# IWRL6432 register map
File version: 1.0
IWRL6432 Radar
CPU: CM4 1.0, other endian, MPU, FPU, 3 interrupt priority bits
Registers are 32-bit, read-write, reset 0x0 unless marked. A register's access mark holds for its fields unless they carry their own. Offsets are from the block's base; lines under a group give offsets from that group; [hi:lo] are bit positions; {n}, {i} and the like mark numbered series; 'fields as' and 'values as' point back to an identical list; <NAME> marks a mode.

## Memory map
0x50F7FC00 GPADC_CTRL size 0x5C
0x53000000 APP_LIN size 0x94
0x53F7F000 APP_UART_0 size 0x94 — APP_UART
0x53F7F400 APP_SPI_0 size 0x1A4 — APP_SPI
0x53F7F800 APP_CANCFG size 0x300
0x53F7FC00 APP_CANECC size 0x310
0x54000000 TPTC_A0 size 0x35C — Register test environment
0x54010000 TPTC_A1 size 0x35C — Register test environment
0x54020000 APP_CRC size 0x148
0x55010000 HWA_CFG size 0x3D8
0x55020000 TPTC_B0 size 0x35C — Register test environment
0x55040000 TPTC_B0_1 size 0x35C — Register test environment
0x55080000 TPCC_B size 0x4020 — TPCC
0x56000000 TPCC_A size 0x4020 — TPCC
0x56040000 APP_RCM size 0x1034
0x56060000 APP_CTRL size 0x1034
0x56080000 APP_HWA_ADCBUF_CTRL size 0x1034
0x56F7EC00 APP_ECC_AGG size 0x310
0x56F7F000 APP_RTI size 0xC0
0x56F7F400 APP_WD size 0xC0
0x56F7F800 APP_DCC size 0x3B
0x56F7FC00 APP_ESM size 0xDC
0x57F7F000 APP_UART_1 size 0x94 — APP_UART
0x57F7F400 APP_SPI_1 size 0x1A4 — APP_SPI
0x57F7F800 APP_I2C size 0x64
0x57F7FC00 APP_PWM size 0x74
0x5A000000 TOP_IO_MUX size 0x70
0x5A040000 APP_PRCM size 0x1C30
0x5AF7FC00 TOP_GIO size 0x154
0x5B020000 TOPSS_CTRL size 0x1034
0x5B040000 PLLDIG_CTRL size 0x1034
0x5C020000 PBIST size 0x1D0
0x5CA00000 TOP_DEBUGSS size 0x12000
0x78000000 APP_CFG_QSPI size 0x74

## TOP_IO_MUX
Base 0x5A000000
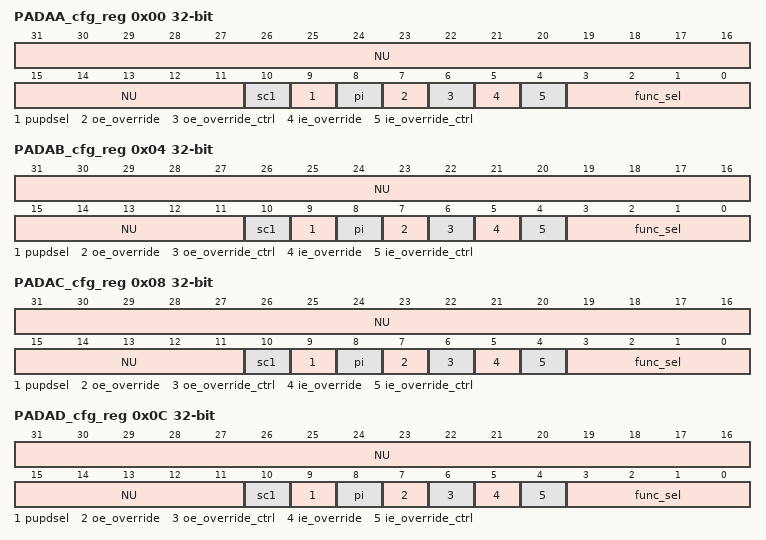
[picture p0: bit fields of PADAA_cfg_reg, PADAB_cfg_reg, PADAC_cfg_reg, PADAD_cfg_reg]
0x00 PADAA_cfg_reg
  [31:11] NU — [31:11] Reserved
  [10] sc1 — [10:10] IO Slew rate control : 0 : higher slew rate. 1: Lower slew rate.
  [9] pupdsel — [9:9] Pullup/PullDown Selection 0 -- Pull Down
  [8] pi — [8:8] Pull Inhibit/Pull Disable 0 -- Enable
  [7] oe_override — [7:7] Active Low Output Override, 0: Output is enabled 1: Output disabled
  [6] oe_override_ctrl — [6:6] Active Low Output Override Control : Write 1 to select Active low Output Override value to control IOs OE_N/GZ instead of the control from hardware
  [5] ie_override — [5:5] Input Override, 1: Input is enabled 0: input disabled (mask the value from the PAD and send only 0 to the core)
  [4] ie_override_ctrl — [4:4] Control to select IE_OVERRIDE : Write 1 to select Override value (IE_OVERRIDE) to control IOs RXACTIVE instead of the control from hardware
  [3:0] func_sel — [3:0] Function select
0x04 PADAB_cfg_reg
  fields as PADAA_cfg_reg
0x08 PADAC_cfg_reg
  fields as PADAA_cfg_reg
0x0C PADAD_cfg_reg
  fields as PADAA_cfg_reg
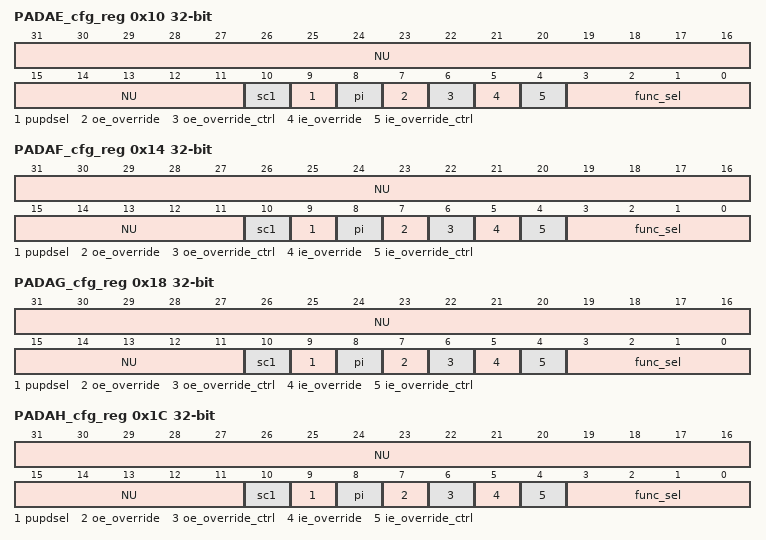
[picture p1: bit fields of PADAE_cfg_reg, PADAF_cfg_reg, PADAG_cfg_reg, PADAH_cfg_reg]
0x10 PADAE_cfg_reg
  fields as PADAA_cfg_reg
0x14 PADAF_cfg_reg
  fields as PADAA_cfg_reg
0x18 PADAG_cfg_reg
  fields as PADAA_cfg_reg
0x1C PADAH_cfg_reg
  fields as PADAA_cfg_reg
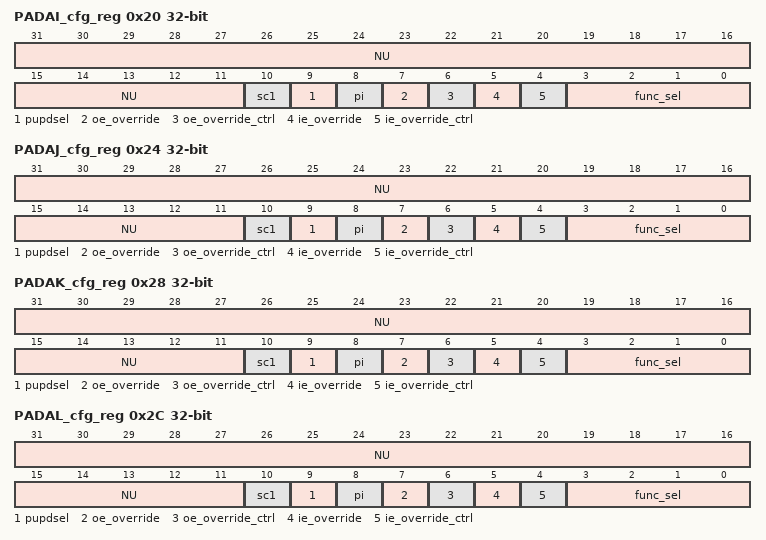
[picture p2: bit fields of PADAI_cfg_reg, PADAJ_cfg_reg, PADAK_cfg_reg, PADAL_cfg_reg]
0x20 PADAI_cfg_reg
  fields as PADAA_cfg_reg
0x24 PADAJ_cfg_reg
  fields as PADAA_cfg_reg
0x28 PADAK_cfg_reg
  fields as PADAA_cfg_reg
0x2C PADAL_cfg_reg
  fields as PADAA_cfg_reg
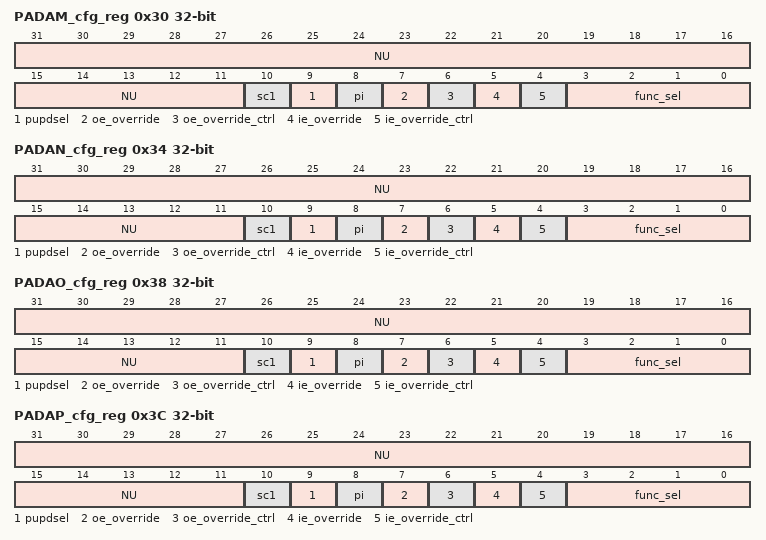
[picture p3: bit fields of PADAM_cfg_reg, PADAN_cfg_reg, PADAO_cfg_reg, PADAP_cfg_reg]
0x30 PADAM_cfg_reg
  fields as PADAA_cfg_reg
0x34 PADAN_cfg_reg
  fields as PADAA_cfg_reg
0x38 PADAO_cfg_reg
  fields as PADAA_cfg_reg
0x3C PADAP_cfg_reg
  fields as PADAA_cfg_reg
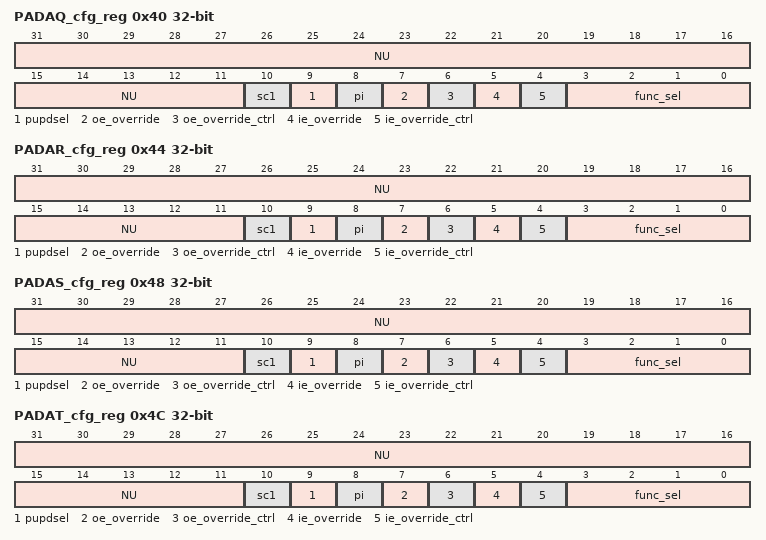
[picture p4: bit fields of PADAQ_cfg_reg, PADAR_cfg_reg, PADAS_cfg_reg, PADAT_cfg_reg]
0x40 PADAQ_cfg_reg
  fields as PADAA_cfg_reg
0x44 PADAR_cfg_reg
  fields as PADAA_cfg_reg
0x48 PADAS_cfg_reg
  fields as PADAA_cfg_reg
0x4C PADAT_cfg_reg
  fields as PADAA_cfg_reg
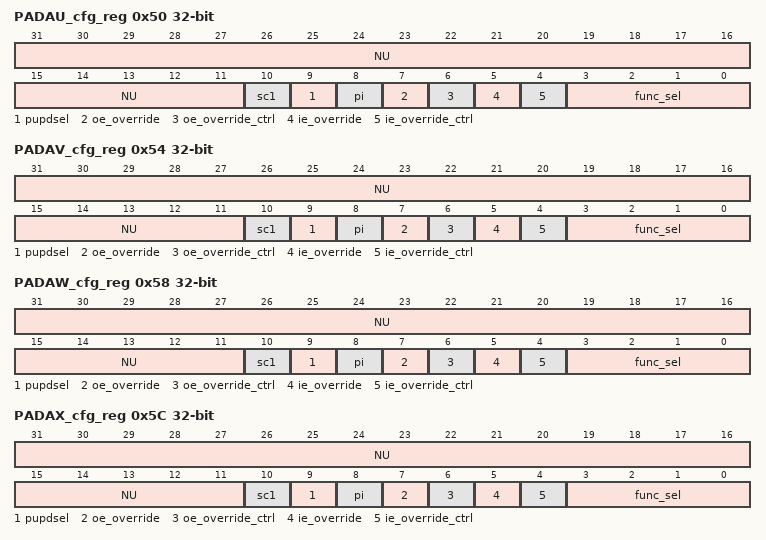
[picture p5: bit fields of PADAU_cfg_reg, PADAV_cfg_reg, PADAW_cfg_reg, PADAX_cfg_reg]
0x50 PADAU_cfg_reg
  fields as PADAA_cfg_reg
0x54 PADAV_cfg_reg
  fields as PADAA_cfg_reg
0x58 PADAW_cfg_reg
  fields as PADAA_cfg_reg
0x5C PADAX_cfg_reg
  fields as PADAA_cfg_reg
0x60 USERMODEEN
  [31:0] USERMODEEN — [31:0] Write 0XADADADAD to enable user mode write access to IO CFG space
0x64 PADGLBLCFGREG
  [31:0] PADGLBLCFGREG — [31:0] 2:0 : global_ie_n_ctl - Write 3'b111 to pass global_ie_n_val to IE_N/RXACTIVE_N pin of all the IOs. 3 : global_ie_n_val - Active low 10:8 : global_oe_n_ctl - Write 3'b111 to pass global_oe_n_val to OE_N/GZ pin of all the IOs. 11 : global_oe_n_val - Active low 18:16 : global_pi_ctl - Write 3'b111 to pass global_pi_val and global_pu_val to all the IOs 19 : global_pi_val 20 : global_pu_val
0x68 IOCFGKICK0
  [31:0] IOCFGKICK0 — [31:0] Kicker 0 Register. The value 83E7 0B13h must be written to KICK0 as part of the process to unlock the CPU write access to the above PIN MUX registers (including IOCFGKICK1)
0x6C IOCFGKICK1
  [31:0] IOCFGKICK1 — [31:0] Kicker 1 Register. The value 95A4 F1E0h must be written to the KICK1 as part of the process to unlock the CPU write access to above PINMUX registers (excluding IOCFGKICK0). IOCFGKICK0 has to be written with 83E70B13h to enable access to IOCFGKICK1.
